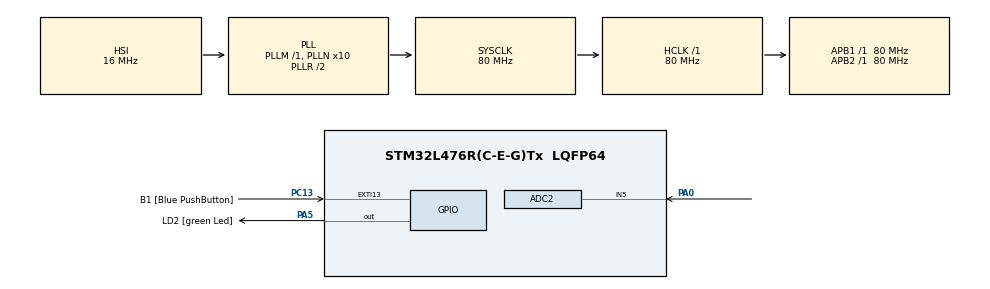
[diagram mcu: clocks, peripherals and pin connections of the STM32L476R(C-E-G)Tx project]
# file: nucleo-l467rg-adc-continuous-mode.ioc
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ADC2.Channel-0\#ChannelRegularConversion=ADC_CHANNEL_5
ADC2.ContinuousConvMode=ENABLE
ADC2.EOCSelection=ADC_EOC_SEQ_CONV
ADC2.NbrOfConversionFlag=1
ADC2.OffsetNumber-0\#ChannelRegularConversion=ADC_OFFSET_NONE
ADC2.Overrun=ADC_OVR_DATA_OVERWRITTEN
ADC2.Rank-0\#ChannelRegularConversion=1
ADC2.SamplingTime-0\#ChannelRegularConversion=ADC_SAMPLETIME_2CYCLES_5
Mcu.Family=STM32L4
Mcu.Name=STM32L476R(C-E-G)Tx
Mcu.Package=LQFP64
NVIC.PriorityGroup=NVIC_PRIORITYGROUP_4
PA0.Signal=ADCx_IN5
PA13\ (JTMS-SWDIO).GPIO_Label=TMS
PA13\ (JTMS-SWDIO).Mode=Serial_Wire
PA13\ (JTMS-SWDIO).Signal=SYS_JTMS-SWDIO
PA14\ (JTCK-SWCLK).GPIO_Label=TCK
PA14\ (JTCK-SWCLK).Mode=Serial_Wire
PA14\ (JTCK-SWCLK).Signal=SYS_JTCK-SWCLK
PA5.GPIO_Label=LD2 [green Led]
PA5.GPIO_ModeDefaultOutputPP=GPIO_MODE_OUTPUT_PP
PA5.GPIO_PuPd=GPIO_NOPULL
PA5.GPIO_Speed=GPIO_SPEED_FREQ_LOW
PA5.Signal=GPIO_Output
PB3\ (JTDO-TRACESWO).GPIO_Label=SWO
PB3\ (JTDO-TRACESWO).Signal=SYS_JTDO-SWO
PC13.GPIO_Label=B1 [Blue PushButton]
PC13.GPIO_ModeDefaultEXTI=GPIO_MODE_IT_FALLING
PC13.GPIO_PuPd=GPIO_NOPULL
PC13.Signal=GPXTI13
PC14-OSC32_IN\ (PC14).Mode=LSE-External-Oscillator
PC14-OSC32_IN\ (PC14).Signal=RCC_OSC32_IN
PC15-OSC32_OUT\ (PC15).Mode=LSE-External-Oscillator
PC15-OSC32_OUT\ (PC15).Signal=RCC_OSC32_OUT
PH0-OSC_IN\ (PH0).Signal=RCC_OSC_IN
PH1-OSC_OUT\ (PH1).Signal=RCC_OSC_OUT
ProjectManager.HeapSize=0x200
ProjectManager.StackSize=0x400
ProjectManager.TargetToolchain=STM32CubeIDE
RCC.ADCFreq_Value=80000000
RCC.AHBFreq_Value=80000000
RCC.APB1Freq_Value=80000000
RCC.APB1TimFreq_Value=80000000
RCC.APB2Freq_Value=80000000
RCC.APB2TimFreq_Value=80000000
RCC.CortexFreq_Value=80000000
RCC.HCLKFreq_Value=80000000
RCC.HSE_VALUE=8000000
RCC.HSI_VALUE=16000000
RCC.MSI_VALUE=4000000
RCC.PLLN=10
RCC.PLLSAI1N=10
RCC.PLLSourceVirtual=RCC_PLLSOURCE_HSI
RCC.PREFETCH_ENABLE=1
RCC.SYSCLKFreq_VALUE=80000000
RCC.SYSCLKSource=RCC_SYSCLKSOURCE_PLLCLK
RCC.USBFreq_Value=80000000
RCC.VCOOutputFreq_Value=160000000
SH.ADCx_IN5.0=ADC1_IN5
SH.ADCx_IN5.1=ADC2_IN5,IN5-Single-Ended
TIM2.AutoReloadPreload=TIM_AUTORELOAD_PRELOAD_ENABLE
TIM2.ClockDivision=TIM_CLOCKDIVISION_DIV2
TIM2.Prescaler=7
VP_TIM2_VS_ClockSourceINT.Mode=Internal
board=NUCLEO-L476RG

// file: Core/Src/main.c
/* USER CODE BEGIN Header */
/**
  ******************************************************************************
  * @file           : main.c
  * @brief          : Main program body
  ******************************************************************************
  * @attention
  *
  * Copyright (c) 2024 STMicroelectronics.
  * All rights reserved.
  *
  * This software is licensed under terms that can be found in the LICENSE file
  * in the root directory of this software component.
  * If no LICENSE file comes with this software, it is provided AS-IS.
  *
  ******************************************************************************
  */
/* USER CODE END Header */
#include "main.h"

/* USER CODE BEGIN PD */
uint16_t adcResult = 0;
uint32_t timerValue1 = 0;
uint32_t timerValue2 = 0;
/* USER CODE END PD */

ADC_HandleTypeDef hadc2;

TIM_HandleTypeDef htim2;

void SystemClock_Config(void);
static void MX_GPIO_Init(void);
static void MX_ADC2_Init(void);
static void MX_TIM2_Init(void);

int main(void)
{

  /* MCU Configuration--------------------------------------------------------*/

  /* Reset of all peripherals, Initializes the Flash interface and the Systick. */
  HAL_Init();

  /* Configure the system clock */
  SystemClock_Config();

  /* Initialize all configured peripherals */
  MX_GPIO_Init();
  MX_ADC2_Init();
  MX_TIM2_Init();
  /* USER CODE BEGIN 2 */
  HAL_ADC_Start(&hadc2);
  HAL_TIM_Base_Start(&htim2);
  /* USER CODE END 2 */

  /* Infinite loop */
  while (1)
  {

    /* USER CODE BEGIN 3 */
		timerValue1 = __HAL_TIM_GET_COUNTER(&htim2);
//		HAL_ADC_PollForConversion(&hadc2,100);
//		adcResult = HAL_ADC_GetValue(&hadc2);
		  while (!((ADC2->ISR) & ADC_ISR_EOC)){;} // wait for EOC (end of conversion) flag is set

		  adcResult = ADC2->DR;
//				HAL_Delay(1000);
		timerValue2 = __HAL_TIM_GET_COUNTER(&htim2);

  }
  /* USER CODE END 3 */
}

void SystemClock_Config(void)
{
  RCC_OscInitTypeDef RCC_OscInitStruct = {0};
  RCC_ClkInitTypeDef RCC_ClkInitStruct = {0};

  /** Configure the main internal regulator output voltage
  */
  if (HAL_PWREx_ControlVoltageScaling(PWR_REGULATOR_VOLTAGE_SCALE1) != HAL_OK)
  {
    Error_Handler();
  }

  /** Initializes the RCC Oscillators according to the specified parameters
  * in the RCC_OscInitTypeDef structure.
  */
  RCC_OscInitStruct.OscillatorType = RCC_OSCILLATORTYPE_HSI;
  RCC_OscInitStruct.HSIState = RCC_HSI_ON;
  RCC_OscInitStruct.HSICalibrationValue = RCC_HSICALIBRATION_DEFAULT;
  RCC_OscInitStruct.PLL.PLLState = RCC_PLL_ON;
  RCC_OscInitStruct.PLL.PLLSource = RCC_PLLSOURCE_HSI;
  RCC_OscInitStruct.PLL.PLLM = 1;
  RCC_OscInitStruct.PLL.PLLN = 10;
  RCC_OscInitStruct.PLL.PLLP = RCC_PLLP_DIV7;
  RCC_OscInitStruct.PLL.PLLQ = RCC_PLLQ_DIV2;
  RCC_OscInitStruct.PLL.PLLR = RCC_PLLR_DIV2;
  if (HAL_RCC_OscConfig(&RCC_OscInitStruct) != HAL_OK)
  {
    Error_Handler();
  }

  /** Initializes the CPU, AHB and APB buses clocks
  */
  RCC_ClkInitStruct.ClockType = RCC_CLOCKTYPE_HCLK|RCC_CLOCKTYPE_SYSCLK
                              |RCC_CLOCKTYPE_PCLK1|RCC_CLOCKTYPE_PCLK2;
  RCC_ClkInitStruct.SYSCLKSource = RCC_SYSCLKSOURCE_PLLCLK;
  RCC_ClkInitStruct.AHBCLKDivider = RCC_SYSCLK_DIV1;
  RCC_ClkInitStruct.APB1CLKDivider = RCC_HCLK_DIV1;
  RCC_ClkInitStruct.APB2CLKDivider = RCC_HCLK_DIV1;

  if (HAL_RCC_ClockConfig(&RCC_ClkInitStruct, FLASH_LATENCY_4) != HAL_OK)
  {
    Error_Handler();
  }
}

static void MX_ADC2_Init(void)
{

  ADC_ChannelConfTypeDef sConfig = {0};

  /** Common config
  */
  hadc2.Instance = ADC2;
  hadc2.Init.ClockPrescaler = ADC_CLOCK_ASYNC_DIV1;
  hadc2.Init.Resolution = ADC_RESOLUTION_12B;
  hadc2.Init.DataAlign = ADC_DATAALIGN_RIGHT;
  hadc2.Init.ScanConvMode = ADC_SCAN_DISABLE;
  hadc2.Init.EOCSelection = ADC_EOC_SEQ_CONV;
  hadc2.Init.LowPowerAutoWait = DISABLE;
  hadc2.Init.ContinuousConvMode = ENABLE;
  hadc2.Init.NbrOfConversion = 1;
  hadc2.Init.DiscontinuousConvMode = DISABLE;
  hadc2.Init.ExternalTrigConv = ADC_SOFTWARE_START;
  hadc2.Init.ExternalTrigConvEdge = ADC_EXTERNALTRIGCONVEDGE_NONE;
  hadc2.Init.DMAContinuousRequests = DISABLE;
  hadc2.Init.Overrun = ADC_OVR_DATA_OVERWRITTEN;
  hadc2.Init.OversamplingMode = DISABLE;
  if (HAL_ADC_Init(&hadc2) != HAL_OK)
  {
    Error_Handler();
  }

  /** Configure Regular Channel
  */
  sConfig.Channel = ADC_CHANNEL_5;
  sConfig.Rank = ADC_REGULAR_RANK_1;
  sConfig.SamplingTime = ADC_SAMPLETIME_2CYCLES_5;
  sConfig.SingleDiff = ADC_SINGLE_ENDED;
  sConfig.OffsetNumber = ADC_OFFSET_NONE;
  sConfig.Offset = 0;
  if (HAL_ADC_ConfigChannel(&hadc2, &sConfig) != HAL_OK)
  {
    Error_Handler();
  }

}

static void MX_TIM2_Init(void)
{

  TIM_ClockConfigTypeDef sClockSourceConfig = {0};
  TIM_MasterConfigTypeDef sMasterConfig = {0};

  htim2.Instance = TIM2;
  htim2.Init.Prescaler = 7;
  htim2.Init.CounterMode = TIM_COUNTERMODE_UP;
  htim2.Init.Period = 4294967295;
  htim2.Init.ClockDivision = TIM_CLOCKDIVISION_DIV2;
  htim2.Init.AutoReloadPreload = TIM_AUTORELOAD_PRELOAD_ENABLE;
  if (HAL_TIM_Base_Init(&htim2) != HAL_OK)
  {
    Error_Handler();
  }
  sClockSourceConfig.ClockSource = TIM_CLOCKSOURCE_INTERNAL;
  if (HAL_TIM_ConfigClockSource(&htim2, &sClockSourceConfig) != HAL_OK)
  {
    Error_Handler();
  }
  sMasterConfig.MasterOutputTrigger = TIM_TRGO_RESET;
  sMasterConfig.MasterSlaveMode = TIM_MASTERSLAVEMODE_DISABLE;
  if (HAL_TIMEx_MasterConfigSynchronization(&htim2, &sMasterConfig) != HAL_OK)
  {
    Error_Handler();
  }

}

static void MX_GPIO_Init(void)
{
  GPIO_InitTypeDef GPIO_InitStruct = {0};

  /* GPIO Ports Clock Enable */
  __HAL_RCC_GPIOC_CLK_ENABLE();
  __HAL_RCC_GPIOH_CLK_ENABLE();
  __HAL_RCC_GPIOA_CLK_ENABLE();
  __HAL_RCC_GPIOB_CLK_ENABLE();

  /*Configure GPIO pin Output Level */
  HAL_GPIO_WritePin(LD2_GPIO_Port, LD2_Pin, GPIO_PIN_RESET);

  /*Configure GPIO pin : B1_Pin */
  GPIO_InitStruct.Pin = B1_Pin;
  GPIO_InitStruct.Mode = GPIO_MODE_IT_FALLING;
  GPIO_InitStruct.Pull = GPIO_NOPULL;
  HAL_GPIO_Init(B1_GPIO_Port, &GPIO_InitStruct);

  /*Configure GPIO pin : PA0 */
  GPIO_InitStruct.Pin = GPIO_PIN_0;
  GPIO_InitStruct.Mode = GPIO_MODE_ANALOG_ADC_CONTROL;
  GPIO_InitStruct.Pull = GPIO_NOPULL;
  HAL_GPIO_Init(GPIOA, &GPIO_InitStruct);

  /*Configure GPIO pin : LD2_Pin */
  GPIO_InitStruct.Pin = LD2_Pin;
  GPIO_InitStruct.Mode = GPIO_MODE_OUTPUT_PP;
  GPIO_InitStruct.Pull = GPIO_NOPULL;
  GPIO_InitStruct.Speed = GPIO_SPEED_FREQ_LOW;
  HAL_GPIO_Init(LD2_GPIO_Port, &GPIO_InitStruct);

}

void Error_Handler(void)
{
  __disable_irq();
  while (1)
  {
  }
}
